AUTOSAR XML (schema 4-2-2)
package /EB/SoftwareComponents
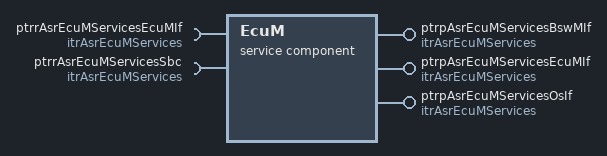
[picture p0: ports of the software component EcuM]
  service sw component type EcuM: category=ASR_Interfaces
    provide port ptrpAsrEcuMServicesBswMIf: provided-interface=itrAsrEcuMServices
    provide port ptrpAsrEcuMServicesEcuMIf: provided-interface=itrAsrEcuMServices
    provide port ptrpAsrEcuMServicesOsIf: provided-interface=itrAsrEcuMServices
    require port ptrrAsrEcuMServicesEcuMIf: required-interface=itrAsrEcuMServices
    require port ptrrAsrEcuMServicesSbc: required-interface=itrAsrEcuMServices
    behavior EcuM_IB: handle-termination-and-restart=NO-SUPPORT
      4 x runnable:
        EcuM_ClearWakeupEvent
        EcuM_GoDown
        EcuM_StartupTwo: external-triggering-point=ptrpAsrEcuMServicesOsIf.EcuM_StartupTwo
        EcuM_ValidateWakeupEvent
package /EB/TriggerInterfaces
  trigger interface itrAsrEcuMServices
    24 x trigger, all with trigger-period={cse-code=1000, cse-code-factor=0}:
      EcuM_AL_DriverInitOne
      EcuM_AL_Reset
      EcuM_AL_SetProgrammableInterrupts
      EcuM_AL_SwitchOff
      EcuM_CheckRamHash
      EcuM_CheckValidation
      EcuM_CheckWakeup
      EcuM_ClearWakeupEvent
      EcuM_DeterminePbConfiguration
      EcuM_DisableWakeupSources
      EcuM_DriverInitListOne
      EcuM_EnableWakeupSources
      EcuM_ErrorHook
      EcuM_GenerateRamHash
      EcuM_GoDown
      EcuM_OnGoOffOne
      EcuM_OnGoOffTwo
      EcuM_PostHalt
      EcuM_PreHalt
      EcuM_SleepActivity
      EcuM_StartWakeupSources
      EcuM_StartupTwo
      EcuM_StopWakeupSources
      EcuM_ValidateWakeupEvent
